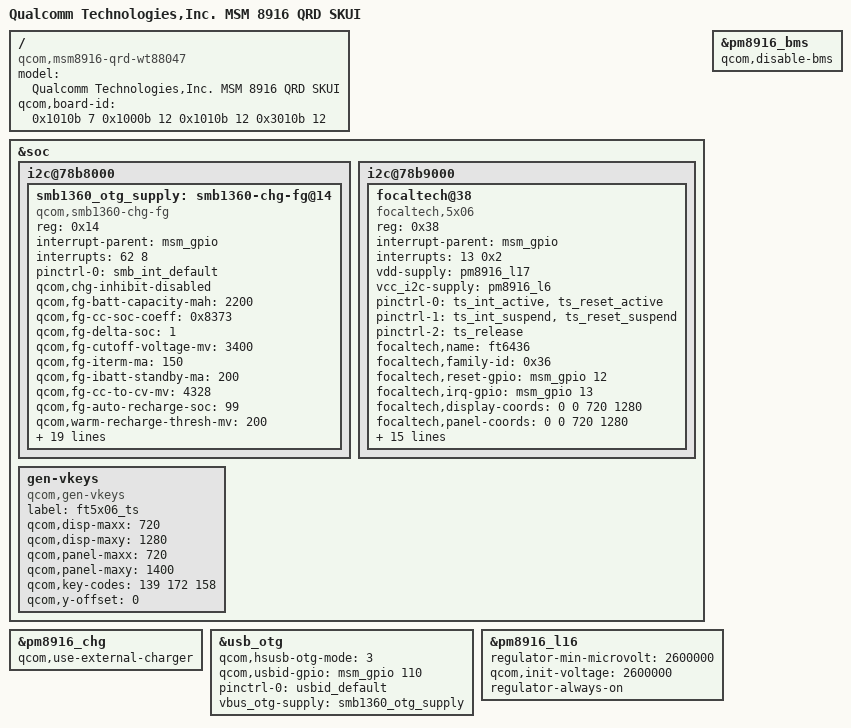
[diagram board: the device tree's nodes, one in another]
/* Copyright (c) 2014, The Linux Foundation. All rights reserved.
 * Copyright (C) 2016 XiaoMi, Inc.
 *
 * This program is free software; you can redistribute it and/or modify
 * it under the terms of the GNU General Public License version 2 and
 * only version 2 as published by the Free Software Foundation.
 *
 * This program is distributed in the hope that it will be useful,
 * but WITHOUT ANY WARRANTY; without even the implied warranty of
 * MERCHANTABILITY or FITNESS FOR A PARTICULAR PURPOSE.  See the
 * GNU General Public License for more details.
 */

/dts-v1/;

#include "msm8916-qrd-wt88047.dtsi"
#include "msm8916-memory.dtsi"

/ {
	model = "Qualcomm Technologies,Inc. MSM 8916 QRD SKUI";
	compatible = "qcom,msm8916-qrd-wt88047","qcom,msm8916-qrd","qcom,msm8916","qcom,qrd";
	qcom,board-id = <0x1010b 7 0x1000b 12 0x1010b 12 0x3010b 12>;
};

&soc {
	i2c@78b8000 {
		smb1360_otg_supply: smb1360-chg-fg@14 {
			compatible = "qcom,smb1360-chg-fg";
			reg = <0x14>;
			interrupt-parent = <&msm_gpio>;
			interrupts = <62 8>;
			pinctrl-names = "default";
			pinctrl-0 = <&smb_int_default>;
			qcom,chg-inhibit-disabled;
			qcom,fg-batt-capacity-mah = <2200>;
			qcom,fg-cc-soc-coeff = <0x8373>;
			qcom,fg-delta-soc =  <1>;
			qcom,fg-cutoff-voltage-mv = <3400>;
			qcom,fg-iterm-ma = <150>;
			qcom,fg-ibatt-standby-ma = <200>;
			qcom,fg-cc-to-cv-mv = <4328>;
			qcom,fg-auto-recharge-soc = <99>;
			qcom,warm-recharge-thresh-mv = <200>;
			qcom,thermistor-c1-coeff = <0x85D2>;
			qcom,float-voltage-mv = <4350>;
			qcom,iterm-ma = <100>;
			qcom,otg-batt-curr-limit = <950>;
			qcom,thermal-mitigation = <1500 700 600 0>;
			qcom,config-hard-thresholds;
			qcom,hot-bat-decidegc = <600>;
			qcom,cold-bat-decidegc = <0>;
			qcom,soft-jeita-supported;
			qcom,warm-bat-decidegc = <450>;
			qcom,cool-bat-decidegc = <100>;
			qcom,warm-bat-mv = <4000>;
			qcom,cool-bat-mv = <4100>;
			qcom,warm-bat-ma = <600>;
			qcom,cool-bat-ma = <600>;
			regulator-name = "smb1360_otg_vreg";
			qcom,shdn-after-pwroff;
			qcom,fg-reset-at-pon;
			qcom,fg-reset-thresold-mv  = <100>;
		};
	};

	i2c@78b9000 {/* BLSP1 QUP5 */
		focaltech@38 {
			compatible = "focaltech,5x06";
			reg = <0x38>;
			interrupt-parent = <&msm_gpio>;
			interrupts = <13 0x2>;
			vdd-supply = <&pm8916_l17>;
			vcc_i2c-supply = <&pm8916_l6>;
			/* pins used by touchscreen */
			pinctrl-names = "pmx_ts_active","pmx_ts_suspend","pmx_ts_release";
			pinctrl-0 = <&ts_int_active &ts_reset_active>;
			pinctrl-1 = <&ts_int_suspend &ts_reset_suspend>;
			pinctrl-2 = <&ts_release>;
			focaltech,name = "ft6436";
			focaltech,family-id = <0x36>;
			focaltech,reset-gpio = <&msm_gpio 12 0x0>;
			focaltech,irq-gpio = <&msm_gpio 13 0x0>;
			focaltech,display-coords = <0 0 720 1280>;
			focaltech,panel-coords = <0 0 720 1280>;
			focaltech,button-map= <139 102 158>;
			focaltech,no-force-update;
			focaltech,i2c-pull-up;
			focaltech,group-id = <1>;
			focaltech,hard-reset-delay-ms = <20>;
			focaltech,soft-reset-delay-ms = <200>;
			focaltech,num-max-touches = <10>;
			focaltech,fw-delay-aa-ms = <30>;
			focaltech,fw-delay-55-ms = <30>;
			focaltech,fw-upgrade-id1 = <0x79>;
			focaltech,fw-upgrade-id2 = <0x18>;
			focaltech,fw-delay-readid-ms = <10>;
			focaltech,fw-delay-era-flsh-ms = <2000>;
			focaltech,fw-auto-cal;
			focaltech,ignore-id-check;
		};
	};

	gen-vkeys {
		compatible = "qcom,gen-vkeys";
		label = "ft5x06_ts";
		qcom,disp-maxx = <720>;
		qcom,disp-maxy = <1280>;
		qcom,panel-maxx = <720>;
		qcom,panel-maxy = <1400>;
		qcom,key-codes = <139 172 158>;
		qcom,y-offset = <0>;
	};
};

&pm8916_chg {
	status = "ok";
	qcom,use-external-charger;
};

&pm8916_bms {
	status = "ok";
	qcom,disable-bms;
};

&usb_otg {
	qcom,hsusb-otg-mode = <3>;
	qcom,usbid-gpio = <&msm_gpio 110 0>;
	pinctrl-names = "default";
	pinctrl-0 = <&usbid_default>;
	vbus_otg-supply = <&smb1360_otg_supply>;
};

&pm8916_l16 {
	regulator-min-microvolt = <2600000>;
	qcom,init-voltage = <2600000>;
	regulator-always-on;
};
